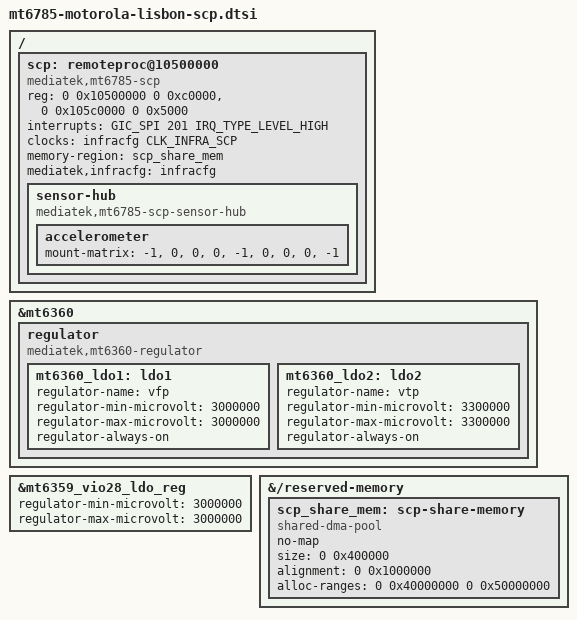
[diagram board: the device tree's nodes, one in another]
// SPDX-License-Identifier: (GPL-2.0 OR MIT)
/*
 * Motorola Moto G60s (lisbon): SCP (Cortex-M4 sensor hub) for the mainline mtk_scp driver.
 *
 * The bootloader loads the scp partition (loader, firmware and DRAM part) into the SCP SRAM and its
 * own reservation, writes the loader parameters to SRAM offset 0x400 and keeps the core in reset;
 * it uses the "mediatek,scp" node of the common dtsi for that, which therefore stays as it is. This
 * node is the one for the driver: same SRAM, CFG block up to and including the clock control
 * registers at 0x4000, interrupt GIC_SPI 201 level high, SRAM size 0xc0000.
 *
 * Shared DRAM for the firmware (logger, sensor FIFO, ...): the firmware uses 3 MiB, 16 MiB aligned,
 * below 0x90000000; the SCP reaches only 0x40000000..0x8fffffff through its address remap. The
 * region here is 4 MiB because the coherent pool hands out power-of-two blocks and mtk_scp takes
 * the 3 MiB in one piece. No fixed reg: the bootloader fills reserved-memory with its own fixed
 * entries.
 *
 * mtk_scp creates a device for the sensor-hub node; the sensor hub driver bound to it starts the
 * core (remoteproc attach to the image loaded by the bootloader) and adds the IIO devices once the
 * hub is set up.
 *
 * sensor-hub: mount matrices for the IIO devices of lisbon-scp-iio. The firmware already turns the
 * chip axes into the device frame (flat, display up: z = +9.8 m/s^2; upright: y = +9.8 m/s^2).
 * iio-sensor-proxy expects the gravity readings with the opposite sign, so the accelerometer gets
 * minus identity. Gyroscope and magnetometer keep the identity.
 *
 * MT6360 LDO1 (VFP, 3.0 V) and LDO2 (VTP, 3.3 V) must be on; the bootloader leaves them off (enable
 * bit 6 of the LDO control register clear, as for the unused LDO3/LDO5). With both off the raw
 * count of the TMD2755 proximity sensor on the hub stays at about 30, covered or not (its IR LED
 * gives no light); with both on it reads about 490 with nothing in front of the sensor. Only these
 * two get constraints here; BUCK1/2 and LDO6/7 (DRAM) are registered without constraints and never
 * switched, LDO3/5 belong to the SD card slot (sd.dtsi).
 *
 * vio28: 3.0 V as in the vendor configuration (the bootloader leaves 2.8 V). The hub and its
 * sensors work the same with 2.8 V and 3.0 V.
 */

&mt6360 {
	regulator {
		compatible = "mediatek,mt6360-regulator";

		mt6360_ldo1: ldo1 {
			regulator-name = "vfp";
			regulator-min-microvolt = <3000000>;
			regulator-max-microvolt = <3000000>;
			regulator-always-on;
		};

		mt6360_ldo2: ldo2 {
			regulator-name = "vtp";
			regulator-min-microvolt = <3300000>;
			regulator-max-microvolt = <3300000>;
			regulator-always-on;
		};
	};
};

&mt6359_vio28_ldo_reg {
	regulator-min-microvolt = <3000000>;
	regulator-max-microvolt = <3000000>;
};

&{/reserved-memory} {
	scp_share_mem: scp-share-memory {
		compatible = "shared-dma-pool";
		no-map;
		size = <0 0x400000>;
		alignment = <0 0x1000000>;
		alloc-ranges = <0 0x40000000 0 0x50000000>;
	};
};

/ {
	scp: remoteproc@10500000 {
		compatible = "mediatek,mt6785-scp";
		reg = <0 0x10500000 0 0xc0000>,
		      <0 0x105c0000 0 0x5000>;
		reg-names = "sram", "cfg";
		interrupts = <GIC_SPI 201 IRQ_TYPE_LEVEL_HIGH>;
		clocks = <&infracfg CLK_INFRA_SCP>;
		clock-names = "main";
		memory-region = <&scp_share_mem>;
		mediatek,infracfg = <&infracfg>;

		sensor-hub {
			compatible = "mediatek,mt6785-scp-sensor-hub";

			accelerometer {
				mount-matrix = "-1", "0", "0",
					       "0", "-1", "0",
					       "0", "0", "-1";
			};
		};
	};
};
